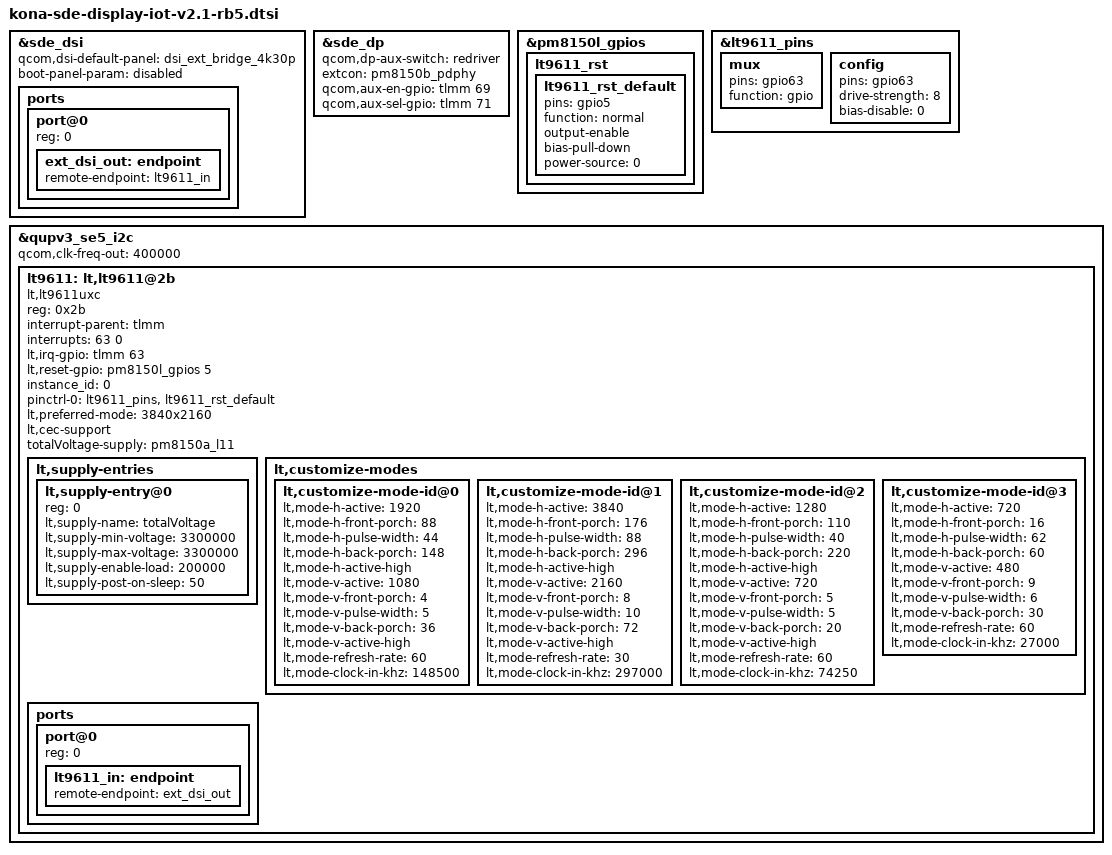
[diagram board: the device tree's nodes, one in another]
#include "kona-sde-display.dtsi"

&sde_dsi {
	qcom,dsi-default-panel = <&dsi_ext_bridge_4k30p>;
	boot-panel-param = "disabled";

	ports {
		#address-cells = <1>;
		#size-cells = <0>;

		port@0 {
			reg = <0>;
			ext_dsi_out: endpoint {
				 remote-endpoint = <&lt9611_in>;
			 };
		};
	};
};

&sde_dp {
	qcom,dp-aux-switch = <&redriver>;
	extcon = <&pm8150b_pdphy>;
	qcom,aux-en-gpio = <&tlmm 69 0>;
	qcom,aux-sel-gpio = <&tlmm 71 0>;
};

&pm8150l_gpios {
	lt9611_rst {
		lt9611_rst_default: lt9611_rst_default {
			pins = "gpio5";
			function = "normal";
			output-enable;
			bias-pull-down;
			power-source = <0>;
		};
	};
};

&lt9611_pins {
	mux {
		pins = "gpio63";
		function = "gpio";
	};

	config {
		pins = "gpio63";
		drive-strength = <8>;
		bias-disable = <0>;
	};
};

&qupv3_se5_i2c {
	status = "okay";
	qcom,clk-freq-out = <400000>;
	lt9611: lt,lt9611@2b {
		compatible = "lt,lt9611uxc";
		reg = <0x2b>;
		interrupt-parent = <&tlmm>;
		interrupts = <63 0>;
		interrupt-names = "lt_irq";
		lt,irq-gpio = <&tlmm 63 0x0>;
		lt,reset-gpio = <&pm8150l_gpios 5 0>;
		instance_id = <0>;

		pinctrl-names = "default";
		pinctrl-0 = <&lt9611_pins &lt9611_rst_default>;

		lt,preferred-mode = "3840x2160";
		lt,cec-support;

		totalVoltage-supply = <&pm8150a_l11>;
		lt,supply-entries {
			#address-cells = <1>;
			#size-cells = <0>;

			lt,supply-entry@0 {
				reg = <0>;
				lt,supply-name = "totalVoltage";
				lt,supply-min-voltage = <3300000>;
				lt,supply-max-voltage = <3300000>;
				lt,supply-enable-load = <200000>;
				lt,supply-post-on-sleep = <50>;
			};
		};

		lt,customize-modes {
			lt,customize-mode-id@0 {
				lt,mode-h-active = <1920>;
				lt,mode-h-front-porch = <88>;
				lt,mode-h-pulse-width = <44>;
				lt,mode-h-back-porch = <148>;
				lt,mode-h-active-high;
				lt,mode-v-active = <1080>;
				lt,mode-v-front-porch = <4>;
				lt,mode-v-pulse-width = <5>;
				lt,mode-v-back-porch = <36>;
				lt,mode-v-active-high;
				lt,mode-refresh-rate = <60>;
				lt,mode-clock-in-khz = <148500>;
			};
			lt,customize-mode-id@1 {
				lt,mode-h-active = <3840>;
				lt,mode-h-front-porch = <176>;
				lt,mode-h-pulse-width = <88>;
				lt,mode-h-back-porch = <296>;
				lt,mode-h-active-high;
				lt,mode-v-active = <2160>;
				lt,mode-v-front-porch = <8>;
				lt,mode-v-pulse-width = <10>;
				lt,mode-v-back-porch = <72>;
				lt,mode-v-active-high;
				lt,mode-refresh-rate = <30>;
				lt,mode-clock-in-khz = <297000>;
			};


			lt,customize-mode-id@2 {
				lt,mode-h-active = <1280>;
				lt,mode-h-front-porch = <110>;
				lt,mode-h-pulse-width = <40>;
				lt,mode-h-back-porch = <220>;
				lt,mode-h-active-high;
				lt,mode-v-active = <720>;
				lt,mode-v-front-porch = <5>;
				lt,mode-v-pulse-width = <5>;
				lt,mode-v-back-porch = <20>;
				lt,mode-v-active-high;
				lt,mode-refresh-rate = <60>;
				lt,mode-clock-in-khz = <74250>;
			};


			lt,customize-mode-id@3 {
				lt,mode-h-active = <720>;
				lt,mode-h-front-porch = <16>;
				lt,mode-h-pulse-width = <62>;
				lt,mode-h-back-porch = <60>;
				lt,mode-v-active = <480>;
				lt,mode-v-front-porch = <9>;
				lt,mode-v-pulse-width = <6>;
				lt,mode-v-back-porch = <30>;
				lt,mode-refresh-rate = <60>;
				lt,mode-clock-in-khz = <27000>;
			};
		};

		ports {
			#address-cells = <1>;
			#size-cells = <0>;

			port@0 {
				reg = <0>;
				lt9611_in: endpoint {
				   remote-endpoint = <&ext_dsi_out>;
			   };
			};
		};
	};
};
